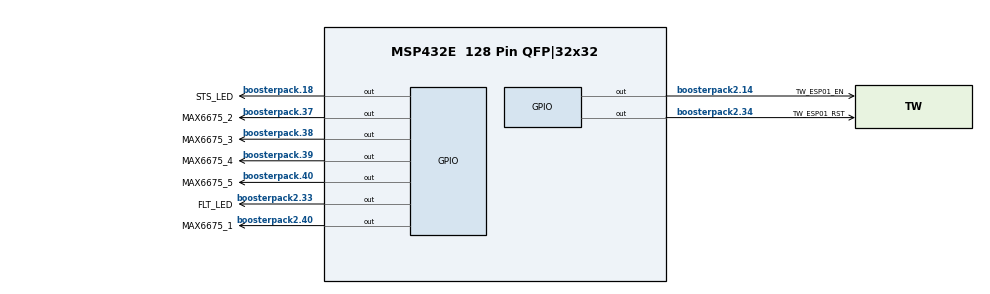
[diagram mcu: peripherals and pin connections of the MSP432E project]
/**
 * @cliArgs --board "/ti/boards/MSP_EXP432E401Y" --device "MSP432E" --part "MSP432E401YTPDT" --package "128 Pin QFP|32x32" --product "simplelink_msp432e4_sdk@4.20.00.12"
 * @versions {"tool":"1.21.0+3721"}
 */

/**
 * Import the modules used in this configuration.
 */
const GPIO   = scripting.addModule("/ti/drivers/GPIO");
const GPIO1  = GPIO.addInstance();
const GPIO2  = GPIO.addInstance();
const GPIO3  = GPIO.addInstance();
const GPIO4  = GPIO.addInstance();
const GPIO5  = GPIO.addInstance();
const GPIO6  = GPIO.addInstance();
const GPIO7  = GPIO.addInstance();
const GPIO8  = GPIO.addInstance();
const GPIO9  = GPIO.addInstance();
const RTOS   = scripting.addModule("/ti/drivers/RTOS");
const SPI    = scripting.addModule("/ti/drivers/SPI", {}, false);
const SPI1   = SPI.addInstance();
const UART   = scripting.addModule("/ti/drivers/UART");
const UART1  = UART.addInstance();
const UART2  = scripting.addModule("/ti/drivers/UART2", {}, false);
const UART21 = UART2.addInstance();

/**
 * Write custom configuration values to the imported modules.
 */
GPIO1.mode            = "Output";
GPIO1.$name           = "STS_LED";
GPIO1.gpioPin.$assign = "boosterpack.18";

GPIO2.$name           = "TW_ESP01_RST";
GPIO2.mode            = "Output";
GPIO2.gpioPin.$assign = "boosterpack2.34";

GPIO3.$name           = "TW_ESP01_EN";
GPIO3.mode            = "Output";
GPIO3.gpioPin.$assign = "boosterpack2.14";

GPIO4.mode            = "Output";
GPIO4.$name           = "FLT_LED";
GPIO4.gpioPin.$assign = "boosterpack2.33";

GPIO5.$name           = "MAX6675_1";
GPIO5.mode            = "Output";
GPIO5.gpioPin.$assign = "boosterpack2.40";

GPIO6.$name           = "MAX6675_2";
GPIO6.mode            = "Output";
GPIO6.gpioPin.$assign = "boosterpack.37";

GPIO7.$name           = "MAX6675_3";
GPIO7.mode            = "Output";
GPIO7.gpioPin.$assign = "boosterpack.38";

GPIO8.$name           = "MAX6675_4";
GPIO8.mode            = "Output";
GPIO8.gpioPin.$assign = "boosterpack.39";

GPIO9.$name           = "MAX6675_5";
GPIO9.mode            = "Output";
GPIO9.gpioPin.$assign = "boosterpack.40";

RTOS.name = "FreeRTOS";

SPI1.$name                = "CONFIG_SPI_MASTER";
SPI1.mode                 = "Four Pin SS Active Low";
SPI1.defaultTxBufferValue = "0xFFFF";
SPI1.spi.$assign          = "SSI2";

UART1.$name = "CONFIG_UART_0";

UART21.$name        = "CONFIG_UART2_0";
UART21.uart.$assign = "UART7";

/**
 * Pinmux solution for unlocked pins/peripherals. This ensures that minor changes to the automatic solver in a future
 * version of the tool will not impact the pinmux you originally saw.  These lines can be completely deleted in order to
 * re-solve from scratch.
 */
SPI1.spi.sclkPin.$suggestSolution         = "boosterpack.7";
SPI1.spi.misoPin.$suggestSolution         = "boosterpack.14";
SPI1.spi.mosiPin.$suggestSolution         = "boosterpack.15";
SPI1.spi.dmaRxChannel.$suggestSolution    = "UDMA_CH12";
SPI1.spi.dmaTxChannel.$suggestSolution    = "UDMA_CH13";
SPI1.spi.ssPin.$suggestSolution           = "boosterpack2.2";
UART1.uart.$suggestSolution               = "UART4";
UART1.uart.txPin.$suggestSolution         = "expansion.8";
UART1.uart.rxPin.$suggestSolution         = "expansion.6";
UART21.uart.txPin.$suggestSolution        = "boosterpack.4";
UART21.uart.dmaTxChannel.$suggestSolution = "UDMA_CH21";
UART21.uart.rxPin.$suggestSolution        = "boosterpack.3";
UART21.uart.dmaRxChannel.$suggestSolution = "UDMA_CH20";
